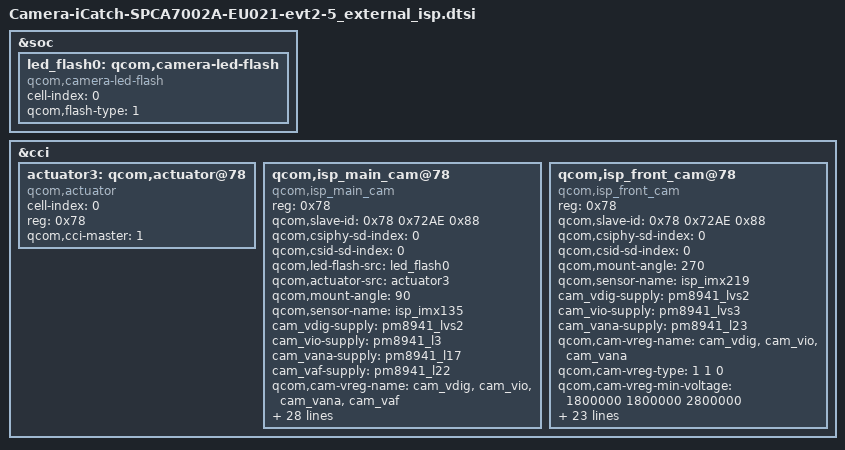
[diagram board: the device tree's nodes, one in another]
&soc {
	led_flash0: qcom,camera-led-flash {
		cell-index = <0>;
		compatible = "qcom,camera-led-flash";
		qcom,flash-type = <1>;
	};
};
&cci {
	actuator3: qcom,actuator@78 {
		cell-index = <0>;
		reg = <0x78>;
		compatible = "qcom,actuator";
		qcom,cci-master = <1>;/*fihtdc,derekcwwu, 20140401, camera uses cci_1*/
	};
	qcom,isp_main_cam@78 {
		compatible = "qcom,isp_main_cam";
		reg = <0x78>;
		qcom,slave-id = <0x78 0x72AE 0x88>;
		qcom,csiphy-sd-index = <0>;
		qcom,csid-sd-index = <0>;
		qcom,led-flash-src = <&led_flash0>;
		qcom,actuator-src = <&actuator3>;
		qcom,mount-angle = <90>;
		qcom,sensor-name = "isp_imx135";
		cam_vdig-supply = <&pm8941_lvs2>;
		cam_vio-supply = <&pm8941_l3>;
		cam_vana-supply = <&pm8941_l17>;
		cam_vaf-supply = <&pm8941_l22>;
		qcom,cam-vreg-name = "cam_vdig", "cam_vio", "cam_vana", "cam_vaf";
		qcom,cam-vreg-type = <1 0 0 0>;
		qcom,cam-vreg-min-voltage = <1800000 1050000 2800000 2800000>;
		qcom,cam-vreg-max-voltage = <1800000 1050000 2800000 2800000>;
		qcom,cam-vreg-op-mode = <1800000 1050000 2800000 2800000>;
		qcom,gpio-no-mux = <0>;
		gpios = <&msmgpio 15 0>,
			<&msmgpio 17 0>,
			<&msmgpio 90 0>,
			<&msmgpio 102 0>,
			<&pm8941_gpios 4 0>,
			<&pm8941_gpios 3 0>,
			<&pm8941_gpios 6 0>,
			<&msmgpio 18 0>,
			<&msmgpio 92 0>;
		qcom,gpio-reset = <2>;
		qcom,gpio-req-tbl-num = <0 1 2 3 4 5 6 7 8>;
		qcom,gpio-req-tbl-flags = <1 2 0 0 0 0 0 0 0>;
		qcom,gpio-req-tbl-label = "ISP_CLK_12M",
					  "ISP_SUSPEND",
					  "ISP_RESET_N",
					  "ISP_INTR",
					  "ISP_AVDD_EN",
					  "ISP_DVDD_EN",
					  "ISP_VCORE_EN",
					  "SENSOR_VIO",
					  "ISP_FLASH_EN";
		qcom,gpio-set-tbl-num = <0 1 2 3 4 5 6 7 8>;
		qcom,gpio-set-tbl-flags = <1 0 0 0 0 0 0 0 0>;
		qcom,gpio-set-tbl-delay = <1000 3000 0 0 0 0 0 50 0>;
		qcom,csi-lane-assign = <0x4320>;
		qcom,csi-lane-mask = <0x1F>;
		qcom,sensor-position = <0>;
		qcom,sensor-mode = <0>;
		qcom,cci-master = <1>;
		firmware_name="PHXEVT2_5";
		status = "ok";
	};
	qcom,isp_front_cam@78 {
		compatible = "qcom,isp_front_cam";
		reg = <0x78>;
		qcom,slave-id = <0x78 0x72AE 0x88>;
		qcom,csiphy-sd-index = <0>;
		qcom,csid-sd-index = <0>;
		qcom,mount-angle = <270>;
		qcom,sensor-name = "isp_imx219";
		cam_vdig-supply = <&pm8941_lvs2>;
		cam_vio-supply = <&pm8941_lvs3>;
		cam_vana-supply = <&pm8941_l23>;
		qcom,cam-vreg-name = "cam_vdig", "cam_vio", "cam_vana";
		qcom,cam-vreg-type = <1 1 0>;
		qcom,cam-vreg-min-voltage = <1800000 1800000 2800000>;
		qcom,cam-vreg-max-voltage = <1800000 1800000 2800000>;
		qcom,cam-vreg-op-mode = <1800000 1800000 2800000>;
		qcom,gpio-no-mux = <0>;
		gpios = <&msmgpio 15 0>,
			<&msmgpio 17 0>,
			<&msmgpio 90 0>,
			<&msmgpio 102 0>,
			<&pm8941_gpios 4 0>,
			<&pm8941_gpios 3 0>,
			<&pm8941_gpios 6 0>,
			<&msmgpio 18 0>;
		qcom,gpio-reset = <2>;
		qcom,gpio-req-tbl-num = <0 1 2 3 4 5 6 7>;
		qcom,gpio-req-tbl-flags = <1 2 0 0 0 0 0 0>;
		qcom,gpio-req-tbl-label = "ISP_CLK_12M",
					  "ISP_SUSPEND",
					  "ISP_RESET_N",
					  "ISP_INTR",
					  "ISP_AVDD_EN",
					  "ISP_DVDD_EN",
					  "ISP_VCORE_EN",
					  "SENSOR_VIO";
		qcom,gpio-set-tbl-num = <0 1 2 3 4 5 6 7>;
		qcom,gpio-set-tbl-flags = <1 0 0 0 0 0 0 0>;
		qcom,gpio-set-tbl-delay = <1000 3000 0 0 0 0 0 0>;
		qcom,csi-lane-assign = <0x4320>;
		qcom,csi-lane-mask = <0x1F>;
		qcom,sensor-position = <1>;
		qcom,sensor-mode = <1>;
		qcom,cci-master = <1>;
		firmware_name="F_PHXEVT2_5";
		status = "ok";
	};
};
